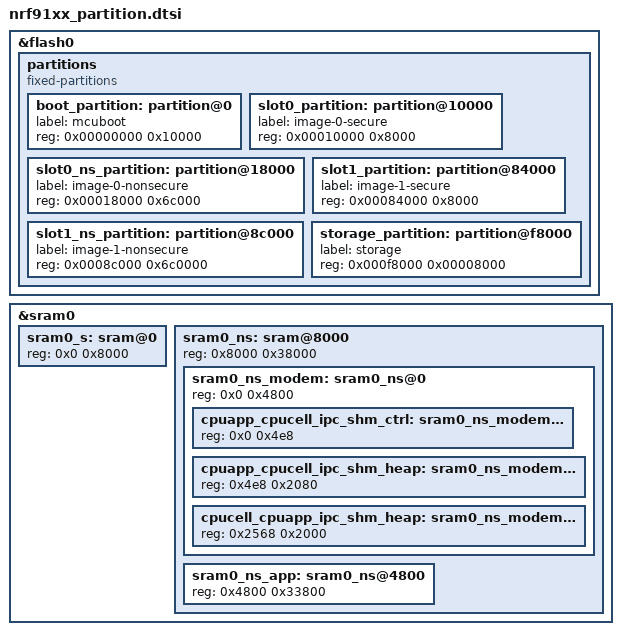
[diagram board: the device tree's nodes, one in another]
/*
 * Copyright 2024 Embeint Inc
 * Copyright (c) 2026 Nordic Semiconductor ASA
 *
 * SPDX-License-Identifier: Apache-2.0
 *
 * Default memory partitioning for nRF91 devices.
 */

&flash0 {
	/*
	 * Default Flash planning for nRF91 series SoCs with MCU boot and minimal TFM.
	 * - Lowest 64 kB allocated to MCU boot.
	 * - Two images, each with Lowest 32 kB allocated to Secure image.
	 * - Highest 32 kB allocated for settings storage.
	 */
	partitions {
		compatible = "fixed-partitions";
		#address-cells = <1>;
		#size-cells = <1>;

		boot_partition: partition@0 {
			label = "mcuboot";
			reg = <0x00000000 0x10000>;
		};

		slot0_partition: partition@10000 {
			label = "image-0-secure";
			reg = <0x00010000 0x8000>;
		};

		slot0_ns_partition: partition@18000 {
			label = "image-0-nonsecure";
			reg = <0x00018000 0x6c000>;
		};

		slot1_partition: partition@84000 {
			label = "image-1-secure";
			reg = <0x00084000 0x8000>;
		};

		slot1_ns_partition: partition@8c000 {
			label = "image-1-nonsecure";
			reg = <0x0008c000 0x6c0000>;
		};

		storage_partition: partition@f8000 {
			label = "storage";
			reg = <0x000f8000 0x00008000>;
		};
	};
};

&sram0 {
	/*
	 * Default SRAM planning for nRF91 series SoCs without MCU boot and minimal TFM.
	 * - Lowest 32 kB SRAM allocated to Secure image (sram0_s).
	 * - Shared section between modem and app cores needs to be in the lower 128 kB.
	 */
	sram0_s: sram@0 {
		/* Secure image memory */
		reg = <0x0 0x8000>;
	};

	sram0_ns: sram@8000 {
		/* Non-Secure image memory */
		reg = <0x8000 0x38000>;
		#address-cells = <1>;
		#size-cells = <1>;
		ranges = <0x0 0x8000 0x38000>;

		sram0_ns_modem: sram0_ns@0 {
			/* Modem (shared) memory */
			reg = <0x0 0x4800>;
			#address-cells = <1>;
			#size-cells = <1>;
			ranges = <0x0 0x0 0x4800>;

			cpuapp_cpucell_ipc_shm_ctrl: sram0_ns_modem@0 {
				/* Modem IPC control */
				reg = <0x0 0x4e8>;
			};

			cpuapp_cpucell_ipc_shm_heap: sram0_ns_modem@4e8 {
				/* Modem IPC transmit */
				reg = <0x4e8 0x2080>;
			};

			cpucell_cpuapp_ipc_shm_heap: sram0_ns_modem@2568 {
				/* Modem IPC receive */
				reg = <0x2568 0x2000>;
			};
		};

		sram0_ns_app: sram0_ns@4800 {
			/* Non-Secure application memory */
			reg = <0x4800 0x33800>;
		};
	};
};
